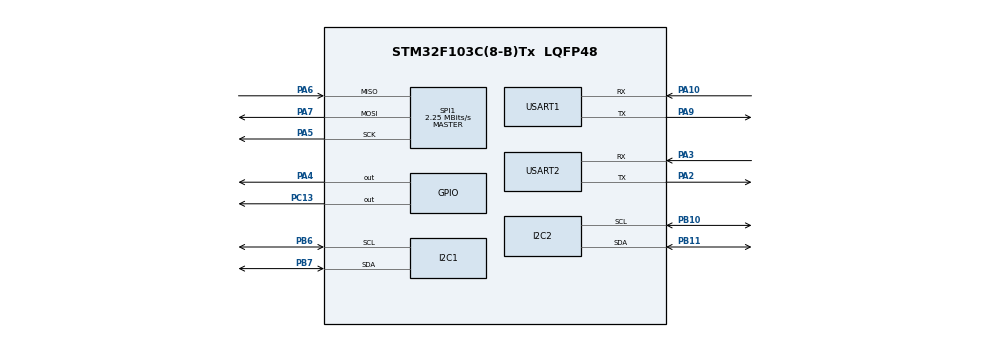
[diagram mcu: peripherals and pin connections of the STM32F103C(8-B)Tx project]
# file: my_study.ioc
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Dma.I2C2_RX.0.Direction=DMA_PERIPH_TO_MEMORY
Dma.I2C2_RX.0.Instance=DMA1_Channel5
Dma.I2C2_RX.0.MemDataAlignment=DMA_MDATAALIGN_BYTE
Dma.I2C2_RX.0.MemInc=DMA_MINC_ENABLE
Dma.I2C2_RX.0.Mode=DMA_NORMAL
Dma.I2C2_RX.0.PeriphDataAlignment=DMA_PDATAALIGN_BYTE
Dma.I2C2_RX.0.PeriphInc=DMA_PINC_DISABLE
Dma.I2C2_RX.0.Priority=DMA_PRIORITY_LOW
Dma.I2C2_TX.1.Direction=DMA_MEMORY_TO_PERIPH
Dma.I2C2_TX.1.Instance=DMA1_Channel4
Dma.I2C2_TX.1.MemDataAlignment=DMA_MDATAALIGN_BYTE
Dma.I2C2_TX.1.MemInc=DMA_MINC_ENABLE
Dma.I2C2_TX.1.Mode=DMA_NORMAL
Dma.I2C2_TX.1.PeriphDataAlignment=DMA_PDATAALIGN_BYTE
Dma.I2C2_TX.1.PeriphInc=DMA_PINC_DISABLE
Dma.I2C2_TX.1.Priority=DMA_PRIORITY_LOW
Dma.Request0=I2C2_RX
Dma.Request1=I2C2_TX
Dma.Request2=USART2_RX
Dma.Request3=USART2_TX
Dma.Request4=SPI1_RX
Dma.Request5=SPI1_TX
Dma.SPI1_RX.4.Direction=DMA_PERIPH_TO_MEMORY
Dma.SPI1_RX.4.Instance=DMA1_Channel2
Dma.SPI1_RX.4.MemDataAlignment=DMA_MDATAALIGN_BYTE
Dma.SPI1_RX.4.MemInc=DMA_MINC_ENABLE
Dma.SPI1_RX.4.Mode=DMA_NORMAL
Dma.SPI1_RX.4.PeriphDataAlignment=DMA_PDATAALIGN_BYTE
Dma.SPI1_RX.4.PeriphInc=DMA_PINC_DISABLE
Dma.SPI1_RX.4.Priority=DMA_PRIORITY_LOW
Dma.SPI1_TX.5.Direction=DMA_MEMORY_TO_PERIPH
Dma.SPI1_TX.5.Instance=DMA1_Channel3
Dma.SPI1_TX.5.MemDataAlignment=DMA_MDATAALIGN_BYTE
Dma.SPI1_TX.5.MemInc=DMA_MINC_ENABLE
Dma.SPI1_TX.5.Mode=DMA_NORMAL
Dma.SPI1_TX.5.PeriphDataAlignment=DMA_PDATAALIGN_BYTE
Dma.SPI1_TX.5.PeriphInc=DMA_PINC_DISABLE
Dma.SPI1_TX.5.Priority=DMA_PRIORITY_LOW
Dma.USART2_RX.2.Direction=DMA_PERIPH_TO_MEMORY
Dma.USART2_RX.2.Instance=DMA1_Channel6
Dma.USART2_RX.2.MemDataAlignment=DMA_MDATAALIGN_BYTE
Dma.USART2_RX.2.MemInc=DMA_MINC_ENABLE
Dma.USART2_RX.2.Mode=DMA_NORMAL
Dma.USART2_RX.2.PeriphDataAlignment=DMA_PDATAALIGN_BYTE
Dma.USART2_RX.2.PeriphInc=DMA_PINC_DISABLE
Dma.USART2_RX.2.Priority=DMA_PRIORITY_LOW
Dma.USART2_TX.3.Direction=DMA_MEMORY_TO_PERIPH
Dma.USART2_TX.3.Instance=DMA1_Channel7
Dma.USART2_TX.3.MemDataAlignment=DMA_MDATAALIGN_BYTE
Dma.USART2_TX.3.MemInc=DMA_MINC_ENABLE
Dma.USART2_TX.3.Mode=DMA_NORMAL
Dma.USART2_TX.3.PeriphDataAlignment=DMA_PDATAALIGN_BYTE
Dma.USART2_TX.3.PeriphInc=DMA_PINC_DISABLE
Dma.USART2_TX.3.Priority=DMA_PRIORITY_LOW
I2C1.I2C_Mode=I2C_Fast
I2C2.I2C_Mode=I2C_Fast
Mcu.Family=STM32F1
Mcu.Name=STM32F103C(8-B)Tx
Mcu.Package=LQFP48
NVIC.DMA1_Channel2_IRQn=true\:0\:0\:false\:false\:true\:false\:true\:true
NVIC.DMA1_Channel3_IRQn=true\:0\:0\:false\:false\:true\:false\:true\:true
NVIC.DMA1_Channel4_IRQn=true\:14\:0\:true\:false\:true\:false\:true\:true
NVIC.DMA1_Channel5_IRQn=true\:13\:0\:true\:false\:true\:false\:true\:true
NVIC.DMA1_Channel6_IRQn=true\:12\:0\:true\:false\:true\:false\:true\:true
NVIC.DMA1_Channel7_IRQn=true\:11\:0\:true\:false\:true\:false\:true\:true
NVIC.I2C1_ER_IRQn=true\:6\:0\:true\:false\:true\:true\:true\:true
NVIC.I2C1_EV_IRQn=true\:6\:0\:true\:false\:true\:true\:true\:true
NVIC.I2C2_ER_IRQn=true\:10\:0\:true\:false\:true\:true\:true\:true
NVIC.I2C2_EV_IRQn=true\:10\:0\:true\:false\:true\:true\:true\:true
NVIC.PriorityGroup=NVIC_PRIORITYGROUP_4
NVIC.SPI1_IRQn=true\:9\:0\:true\:false\:true\:true\:true\:true
NVIC.USART1_IRQn=true\:7\:0\:true\:false\:true\:true\:true\:true
NVIC.USART2_IRQn=true\:8\:0\:true\:false\:true\:false\:true\:true
PA10.GPIO_Mode=GPIO_MODE_INPUT
PA10.Mode=Asynchronous
PA10.Signal=USART1_RX
PA13.Mode=Serial_Wire
PA13.Signal=SYS_JTMS-SWDIO
PA14.Mode=Serial_Wire
PA14.Signal=SYS_JTCK-SWCLK
PA2.GPIO_Mode=GPIO_MODE_AF_PP
PA2.Mode=Asynchronous
PA2.Signal=USART2_TX
PA3.GPIO_Mode=GPIO_MODE_INPUT
PA3.Mode=Asynchronous
PA3.Signal=USART2_RX
PA4.PinState=GPIO_PIN_SET
PA4.Signal=GPIO_Output
PA5.Mode=Full_Duplex_Master
PA5.Signal=SPI1_SCK
PA6.Mode=Full_Duplex_Master
PA6.Signal=SPI1_MISO
PA7.Mode=Full_Duplex_Master
PA7.Signal=SPI1_MOSI
PA9.GPIO_Mode=GPIO_MODE_AF_PP
PA9.Mode=Asynchronous
PA9.Signal=USART1_TX
PB10.Mode=I2C
PB10.Signal=I2C2_SCL
PB11.Mode=I2C
PB11.Signal=I2C2_SDA
PB6.Mode=I2C
PB6.Signal=I2C1_SCL
PB7.Mode=I2C
PB7.Signal=I2C1_SDA
PC13-TAMPER-RTC.GPIO_ModeDefaultOutputPP=GPIO_MODE_OUTPUT_OD
PC13-TAMPER-RTC.GPIO_PuPd=GPIO_NOPULL
PC13-TAMPER-RTC.GPIO_Speed=GPIO_SPEED_FREQ_HIGH
PC13-TAMPER-RTC.PinState=GPIO_PIN_SET
PC13-TAMPER-RTC.Signal=GPIO_Output
PD0-OSC_IN.Mode=HSE-External-Oscillator
PD0-OSC_IN.Signal=RCC_OSC_IN
PD1-OSC_OUT.Mode=HSE-External-Oscillator
PD1-OSC_OUT.Signal=RCC_OSC_OUT
ProjectManager.HeapSize=0x200
ProjectManager.StackSize=0x800
ProjectManager.TargetToolchain=MDK-ARM V5.32
RCC.AHBFreq_Value=72000000
RCC.APB1CLKDivider=RCC_HCLK_DIV2
RCC.APB1Freq_Value=36000000
RCC.APB1TimFreq_Value=72000000
RCC.APB2Freq_Value=72000000
RCC.APB2TimFreq_Value=72000000
RCC.HCLKFreq_Value=72000000
RCC.PLLMUL=RCC_PLL_MUL9
RCC.PLLSourceVirtual=RCC_PLLSOURCE_HSE
RCC.SYSCLKFreq_VALUE=72000000
RCC.SYSCLKSource=RCC_SYSCLKSOURCE_PLLCLK
RCC.USBFreq_Value=72000000
SPI1.BaudRatePrescaler=SPI_BAUDRATEPRESCALER_32
SPI1.CalculateBaudRate=2.25 MBits/s
SPI1.Direction=SPI_DIRECTION_2LINES
SPI1.Mode=SPI_MODE_MASTER
SPI1.VirtualType=VM_MASTER
USART1.VirtualMode=VM_ASYNC
USART2.VirtualMode=VM_ASYNC
board=custom

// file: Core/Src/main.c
/* USER CODE BEGIN Header */
/**
  ******************************************************************************
  * @file           : main.c
  * @brief          : Main program body
  ******************************************************************************
  * @attention
  *
  * Copyright (c) 2025 STMicroelectronics.
  * All rights reserved.
  *
  * This software is licensed under terms that can be found in the LICENSE file
  * in the root directory of this software component.
  * If no LICENSE file comes with this software, it is provided AS-IS.
  *
  ******************************************************************************
  */
  /* USER CODE END Header */
  /* Includes ------------------------------------------------------------------*/
#include "main.h"
#include "dma.h"
#include "i2c.h"
#include "spi.h"
#include "usart.h"
#include "gpio.h"

void SystemClock_Config (void);

int main (void)
{

  /* MCU Configuration--------------------------------------------------------*/

  /* Reset of all peripherals, Initializes the Flash interface and the Systick. */
  LL_APB2_GRP1_EnableClock (LL_APB2_GRP1_PERIPH_AFIO);
  LL_APB1_GRP1_EnableClock (LL_APB1_GRP1_PERIPH_PWR);

  /* System interrupt init*/
  NVIC_SetPriorityGrouping (NVIC_PRIORITYGROUP_4);

  /* SysTick_IRQn interrupt configuration */
  NVIC_SetPriority (SysTick_IRQn , NVIC_EncodePriority (NVIC_GetPriorityGrouping ( ) , 15 , 0));

  /** NOJTAG: JTAG-DP Disabled and SW-DP Enabled
  */
  LL_GPIO_AF_Remap_SWJ_NOJTAG ( );

  /* Configure the system clock */
  SystemClock_Config ( );

  /* Initialize all configured peripherals */
  MX_GPIO_Init ( );
  MX_DMA_Init ( );
  MX_I2C2_Init ( );
  MX_USART2_UART_Init ( );
  MX_SPI1_Init ( );
  MX_I2C1_Init ( );
  MX_USART1_UART_Init ( );
  /* USER CODE BEGIN 2 */

  //测试串口重定向 显示系统主频
  USART2_Redirected_test ( );
  my_W25Q16M_Init ( );
  /* USER CODE END 2 */

  /* Infinite loop */
  while (1)
  {

  }
}

void SystemClock_Config (void)
{
  LL_FLASH_SetLatency (LL_FLASH_LATENCY_2);
  while (LL_FLASH_GetLatency ( ) != LL_FLASH_LATENCY_2)
  {
  }
  LL_RCC_HSE_Enable ( );

  /* Wait till HSE is ready */
  while (LL_RCC_HSE_IsReady ( ) != 1)
  {

  }
  LL_RCC_PLL_ConfigDomain_SYS (LL_RCC_PLLSOURCE_HSE_DIV_1 , LL_RCC_PLL_MUL_9);
  LL_RCC_PLL_Enable ( );

  /* Wait till PLL is ready */
  while (LL_RCC_PLL_IsReady ( ) != 1)
  {

  }
  LL_RCC_SetAHBPrescaler (LL_RCC_SYSCLK_DIV_1);
  LL_RCC_SetAPB1Prescaler (LL_RCC_APB1_DIV_2);
  LL_RCC_SetAPB2Prescaler (LL_RCC_APB2_DIV_1);
  LL_RCC_SetSysClkSource (LL_RCC_SYS_CLKSOURCE_PLL);

  /* Wait till System clock is ready */
  while (LL_RCC_GetSysClkSource ( ) != LL_RCC_SYS_CLKSOURCE_STATUS_PLL)
  {

  }
  LL_Init1msTick (72000000);
  LL_SetSystemCoreClock (72000000);
}

void Error_Handler (void)
{
  /* USER CODE BEGIN Error_Handler_Debug */

  /* User can add his own implementation to report the HAL error return state */
  __disable_irq ( );
  while (1)
  {
    //系统指示灯闪烁3秒,间隔500毫秒
    my_Onboard_LED_msToggle (500 , 6);

    //软重启
    //NVIC_SystemReset ( );

  }
  /* USER CODE END Error_Handler_Debug */
}
